# i2c_ctrl: IP-XACT component
VLNV tenstorrent.com:ocah:i2c_ctrl:1.0

## Address spaces and blocks
i2c_ctrl_mmap.i2c_ctrl: base 'h0, range 'hc, width 32

## Registers
Registers are 32-bit, read-write, reset 0x0 unless marked. A register's access mark holds for its fields unless they carry their own. Offsets are from the block's base; lines under a group give offsets from that group; [hi:lo] are bit positions; {n}, {i} and the like mark numbered series; 'fields as' and 'values as' point back to an identical list; <NAME> marks a mode.

## i2c_ctrl_mmap.i2c_ctrl — Per-instance pad-function select, SMBus pad direction, and SMBus alert enable.
Base 0x00000000
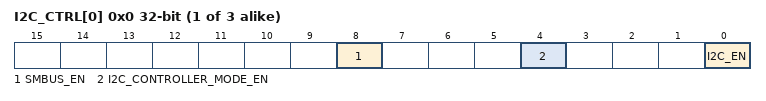
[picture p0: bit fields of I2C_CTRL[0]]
{0x0+4i} I2C_CTRL[{i}] (i=0..2) — Control Register
  [8] SMBUS_EN — SMBus Enable. Gates the SMBus Alert signal.
  [4] I2C_CONTROLLER_MODE_EN — SMBus Pad Direction. When set, the SMBus alert pad is an input and the SMBus suspend pad is an output, as for an SMBus host. When clear, the alert pad is an output and the suspend pad is an input, as for an SMBus target. SCL and SDA are unaffected. Program it to agree with the core's CTRL.ENABLEHOST and CTRL.ENABLETARGET setting.
  [0] I2C_EN — I2C Pad Function Select. When set, the integration routes this instance's SCL, SDA, SMBus alert and SMBus suspend signals to their pads. Does not enable the I2C core; CTRL.ENABLEHOST and CTRL.ENABLETARGET select the core's operating mode.

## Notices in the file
SPDX-License-Identifier: Apache-2.0
SPDX-FileCopyrightText: 2026 Tenstorrent USA, Inc.
